# USB_USB2SS_USB2SS_DEBUG_TRACE_0F080000h register map
Vendor: Texas Instruments
Peripheral module from a debugger description file (folder am62L).
Registers are 32-bit, read-write, reset 0x0 unless marked. A register's access mark holds for its fields unless they carry their own. Offsets are as the file gives them; lines under a group give offsets from that group; [hi:lo] are bit positions; {n}, {i} and the like mark numbered series; 'fields as' and 'values as' point back to an identical list; <NAME> marks a mode.

## USB2SS_USB2SS_DEBUG_TRACE
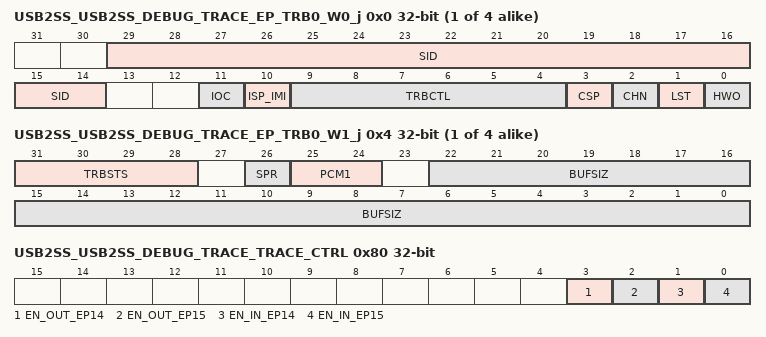
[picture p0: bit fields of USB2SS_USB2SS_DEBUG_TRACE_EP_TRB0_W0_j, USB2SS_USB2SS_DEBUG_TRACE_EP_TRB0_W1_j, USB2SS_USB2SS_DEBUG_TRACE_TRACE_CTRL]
{0x0+0x10*i} USB2SS_USB2SS_DEBUG_TRACE_EP_TRB{i}_W0_j (i=0..3) — TRB{i} Word 0. Please refer to Controller programming guide for more details on these fields.
  [29:14] SID — Stream ID / SOF Number Reset Source: cfg_srst_n
  [11] IOC — Interrupt on Complete Reset Source: cfg_srst_n
  [10] ISP_IMI — Interrupt on Short Packet / Interrupt on Missed ISOC Reset Source: cfg_srst_n
  [9:4] TRBCTL — Indicates the type of TRB Reset Source: cfg_srst_n
  [3] CSP — Continue on Short Packet Reset Source: cfg_srst_n
  [2] CHN — Chain buffers Reset Source: cfg_srst_n
  [1] LST — Indicates this is the last TRB in a list Reset Source: cfg_srst_n
  [0] HWO — Hardware Owner of Descriptor Reset Source: cfg_srst_n
{0x4+0x10*i} USB2SS_USB2SS_DEBUG_TRACE_EP_TRB{i}_W1_j (i=0..3) — TRB{i} Word 1. Please refer to Controller programming guide for more details on these fields.
  [31:28] TRBSTS — Packet Count M1 Reset Source: cfg_srst_n
  [26] SPR — Short packet received/Reserved bits Reset Source: cfg_srst_n
  [25:24] PCM1 — Packet Count M1 Reset Source: cfg_srst_n
  [22:0] BUFSIZ — Buffer Size Reset Source: cfg_srst_n
{0x8+0x10*i} USB2SS_USB2SS_DEBUG_TRACE_EP_TRB{i}_W2_j (i=0..3) — TRB{i} Word 2. Please refer to Controller programming guide for more details on these fields.
  [31:0] BPTRH — Buffer Pointer High Reset Source: cfg_srst_n
{0xC+0x10*i} USB2SS_USB2SS_DEBUG_TRACE_EP_TRB{i}_W3_j (i=0..3) — TRB{i} Word 3. Please refer to Controller programming guide for more details on these fields.
  [31:0] BPTRL — Buffer Pointer Low Reset Source: cfg_srst_n
0x80 USB2SS_USB2SS_DEBUG_TRACE_TRACE_CTRL access per field — Debug trace control register
  [3] EN_OUT_EP14 rw — Debug trace enable for OUT Endpoint 14 Reset Source: cfg_srst_n
  [2] EN_OUT_EP15 rw — Debug trace enable for OUT Endpoint 15 Reset Source: cfg_srst_n
  [1] EN_IN_EP14 rw — Debug trace enable for IN Endpoint 14 Reset Source: cfg_srst_n
  [0] EN_IN_EP15 rw — Debug trace enable for IN Endpoint 15 Reset Source: cfg_srst_n
